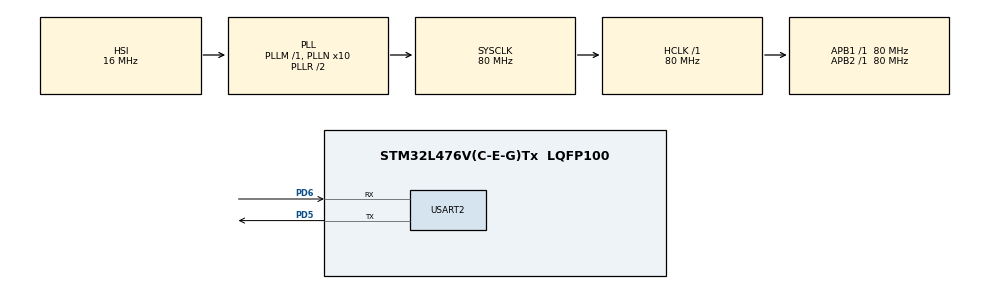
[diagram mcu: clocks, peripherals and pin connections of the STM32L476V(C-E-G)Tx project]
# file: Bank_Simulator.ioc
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FREERTOS.Tasks01=defaultTask,24,128,StartDefaultTask,Default,NULL
FREERTOS.configTOTAL_HEAP_SIZE=15000
Mcu.Family=STM32L4
Mcu.Name=STM32L476V(C-E-G)Tx
Mcu.Package=LQFP100
NVIC.PriorityGroup=NVIC_PRIORITYGROUP_4
NVIC.TIM1_UP_TIM16_IRQn=true\:0\:0\:false\:false\:true\:false\:false\:true
NVIC.TimeBase=TIM1_UP_TIM16_IRQn
NVIC.TimeBaseIP=TIM1
PD5.Mode=Asynchronous
PD5.Signal=USART2_TX
PD6.Mode=Asynchronous
PD6.Signal=USART2_RX
ProjectManager.HeapSize=0x200
ProjectManager.StackSize=0x400
ProjectManager.TargetToolchain=MDK-ARM V5
RCC.ADCFreq_Value=64000000
RCC.AHBFreq_Value=80000000
RCC.APB1Freq_Value=80000000
RCC.APB1TimFreq_Value=80000000
RCC.APB2Freq_Value=80000000
RCC.APB2TimFreq_Value=80000000
RCC.CortexFreq_Value=80000000
RCC.HCLKFreq_Value=80000000
RCC.HSE_VALUE=8000000
RCC.HSI_VALUE=16000000
RCC.LSE_VALUE=32768
RCC.MSI_VALUE=4000000
RCC.PLLN=10
RCC.PLLSAI1Q=RCC_PLLQ_DIV4
RCC.PLLSourceVirtual=RCC_PLLSOURCE_HSI
RCC.SYSCLKFreq_VALUE=80000000
RCC.SYSCLKSource=RCC_SYSCLKSOURCE_PLLCLK
RCC.USBFreq_Value=32000000
RCC.VCOOutputFreq_Value=160000000
TIM2.Period=0xffffffff
TIM2.Prescaler=159
USART2.VirtualMode-Asynchronous=VM_ASYNC
VP_FREERTOS_VS_CMSIS_V2.Mode=CMSIS_V2
VP_RNG_VS_RNG.Mode=RNG_Activate
VP_SYS_VS_tim1.Mode=TIM1
VP_TIM2_VS_ClockSourceINT.Mode=Internal
board=custom

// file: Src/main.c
/* USER CODE BEGIN Header */
/**
  ******************************************************************************
  * @file           : main.c
  * @brief          : Main program body
  ******************************************************************************
  * @attention
  *
  * <h2><center>&copy; Copyright (c) 2019 STMicroelectronics.
  * All rights reserved.</center></h2>
  *
  * This software component is licensed by ST under Ultimate Liberty license
  * SLA0044, the "License"; You may not use this file except in compliance with
  * the License. You may obtain a copy of the License at:
  *                             www.st.com/SLA0044
  *
  ******************************************************************************
  */
/* USER CODE END Header */

#include "main.h"
#include "cmsis_os.h"
#include "rng.h"
#include "tim.h"
#include "usart.h"
#include "gpio.h"
#include "people.h"
#include "task.h"
#include "stddef.h"
#include "stdint.h"
#include "job.h"
#include <stdio.h>

void SystemClock_Config(void);
void MX_FREERTOS_Init(void);
extern uint8_t buffer[];
bank bank_sim;

int main(void)
{
	/* Reset of all peripherals, Initializes the Flash interface and the Systick. */
	HAL_Init();

	/* Configure the system clock */
	SystemClock_Config();

	/* Initialize all configured peripherals */
	MX_GPIO_Init();
	MX_RNG_Init();
	MX_TIM2_Init();
	MX_USART2_UART_Init();

	/* USER CODE BEGIN 2 */
	init_bank();
	create_tasks();

	/* USER CODE END 2 */

	/* Call init function for freertos objects (in freertos.c) */
	MX_FREERTOS_Init();

	/* Start scheduler */

	osKernelStart();

	/* We should never get here as control is now taken by the scheduler */

	/* Infinite loop */
	/* USER CODE BEGIN WHILE */
	while (1)
	{

	}
}

void SystemClock_Config(void)
{
  RCC_OscInitTypeDef RCC_OscInitStruct = {0};
  RCC_ClkInitTypeDef RCC_ClkInitStruct = {0};
  RCC_PeriphCLKInitTypeDef PeriphClkInit = {0};

  /** Initializes the CPU, AHB and APB busses clocks
  */
  RCC_OscInitStruct.OscillatorType = RCC_OSCILLATORTYPE_HSI;
  RCC_OscInitStruct.HSIState = RCC_HSI_ON;
  RCC_OscInitStruct.HSICalibrationValue = RCC_HSICALIBRATION_DEFAULT;
  RCC_OscInitStruct.PLL.PLLState = RCC_PLL_ON;
  RCC_OscInitStruct.PLL.PLLSource = RCC_PLLSOURCE_HSI;
  RCC_OscInitStruct.PLL.PLLM = 1;
  RCC_OscInitStruct.PLL.PLLN = 10;
  RCC_OscInitStruct.PLL.PLLP = RCC_PLLP_DIV7;
  RCC_OscInitStruct.PLL.PLLQ = RCC_PLLQ_DIV2;
  RCC_OscInitStruct.PLL.PLLR = RCC_PLLR_DIV2;
  if (HAL_RCC_OscConfig(&RCC_OscInitStruct) != HAL_OK)
  {
    Error_Handler();
  }
  /** Initializes the CPU, AHB and APB busses clocks
  */
  RCC_ClkInitStruct.ClockType = RCC_CLOCKTYPE_HCLK|RCC_CLOCKTYPE_SYSCLK
                              |RCC_CLOCKTYPE_PCLK1|RCC_CLOCKTYPE_PCLK2;
  RCC_ClkInitStruct.SYSCLKSource = RCC_SYSCLKSOURCE_PLLCLK;
  RCC_ClkInitStruct.AHBCLKDivider = RCC_SYSCLK_DIV1;
  RCC_ClkInitStruct.APB1CLKDivider = RCC_HCLK_DIV1;
  RCC_ClkInitStruct.APB2CLKDivider = RCC_HCLK_DIV1;

  if (HAL_RCC_ClockConfig(&RCC_ClkInitStruct, FLASH_LATENCY_4) != HAL_OK)
  {
    Error_Handler();
  }
  PeriphClkInit.PeriphClockSelection = RCC_PERIPHCLK_USART2|RCC_PERIPHCLK_RNG;
  PeriphClkInit.Usart2ClockSelection = RCC_USART2CLKSOURCE_PCLK1;
  PeriphClkInit.RngClockSelection = RCC_RNGCLKSOURCE_PLLSAI1;
  PeriphClkInit.PLLSAI1.PLLSAI1Source = RCC_PLLSOURCE_HSI;
  PeriphClkInit.PLLSAI1.PLLSAI1M = 1;
  PeriphClkInit.PLLSAI1.PLLSAI1N = 8;
  PeriphClkInit.PLLSAI1.PLLSAI1P = RCC_PLLP_DIV7;
  PeriphClkInit.PLLSAI1.PLLSAI1Q = RCC_PLLQ_DIV4;
  PeriphClkInit.PLLSAI1.PLLSAI1R = RCC_PLLR_DIV2;
  PeriphClkInit.PLLSAI1.PLLSAI1ClockOut = RCC_PLLSAI1_48M2CLK;
  if (HAL_RCCEx_PeriphCLKConfig(&PeriphClkInit) != HAL_OK)
  {
    Error_Handler();
  }
  /** Configure the main internal regulator output voltage
  */
  if (HAL_PWREx_ControlVoltageScaling(PWR_REGULATOR_VOLTAGE_SCALE1) != HAL_OK)
  {
    Error_Handler();
  }
}

void HAL_TIM_PeriodElapsedCallback(TIM_HandleTypeDef *htim)
{
  if (htim->Instance == TIM1) {
    HAL_IncTick();
  }
}

void Error_Handler(void)
{
}

/************************ (C) COPYRIGHT STMicroelectronics *****END OF FILE****/
